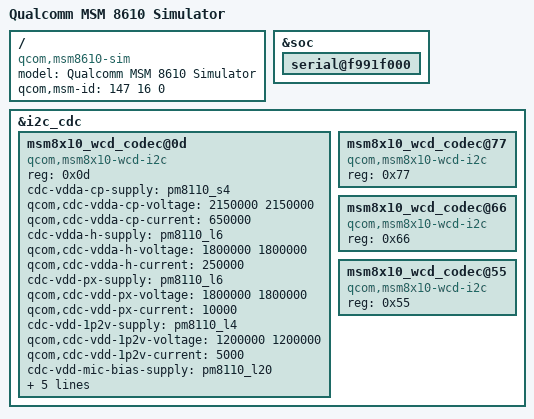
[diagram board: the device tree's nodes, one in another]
/* Copyright (c) 2012-2013, The Linux Foundation. All rights reserved.
 *
 * This program is free software; you can redistribute it and/or modify
 * it under the terms of the GNU General Public License version 2 and
 * only version 2 as published by the Free Software Foundation.
 *
 * This program is distributed in the hope that it will be useful,
 * but WITHOUT ANY WARRANTY; without even the implied warranty of
 * MERCHANTABILITY or FITNESS FOR A PARTICULAR PURPOSE.  See the
 * GNU General Public License for more details.
 */

/dts-v1/;

/include/ "msm8610.dtsi"

/ {
	model = "Qualcomm MSM 8610 Simulator";
	compatible = "qcom,msm8610-sim", "qcom,msm8610", "qcom,sim";
	qcom,msm-id = <147 16 0>;
};

&soc {
	serial@f991f000 {
		status = "ok";
	};
};

&i2c_cdc  {
	msm8x10_wcd_codec@0d{
		compatible = "qcom,msm8x10-wcd-i2c";
		reg = <0x0d>;
		cdc-vdda-cp-supply = <&pm8110_s4>;
		qcom,cdc-vdda-cp-voltage = <2150000 2150000>;
		qcom,cdc-vdda-cp-current = <650000>;

		cdc-vdda-h-supply = <&pm8110_l6>;
		qcom,cdc-vdda-h-voltage = <1800000 1800000>;
		qcom,cdc-vdda-h-current = <250000>;

		cdc-vdd-px-supply = <&pm8110_l6>;
		qcom,cdc-vdd-px-voltage = <1800000 1800000>;
		qcom,cdc-vdd-px-current = <10000>;

		cdc-vdd-1p2v-supply = <&pm8110_l4>;
		qcom,cdc-vdd-1p2v-voltage = <1200000 1200000>;
		qcom,cdc-vdd-1p2v-current = <5000>;

		cdc-vdd-mic-bias-supply = <&pm8110_l20>;
		qcom,cdc-vdd-mic-bias-voltage = <3075000 3075000>;
		qcom,cdc-vdd-mic-bias-current = <25000>;

		qcom,cdc-micbias-cfilt-sel = <0x0>;
		qcom,cdc-micbias-cfilt-mv = <1800000>;
		qcom,cdc-mclk-clk-rate = <12288000>;
	};

	msm8x10_wcd_codec@77{
		compatible = "qcom,msm8x10-wcd-i2c";
		reg = <0x77>;
	};

	msm8x10_wcd_codec@66{
		compatible = "qcom,msm8x10-wcd-i2c";
		reg = <0x66>;
	};

	msm8x10_wcd_codec@55{
		compatible = "qcom,msm8x10-wcd-i2c";
		reg = <0x55>;
	};
};
